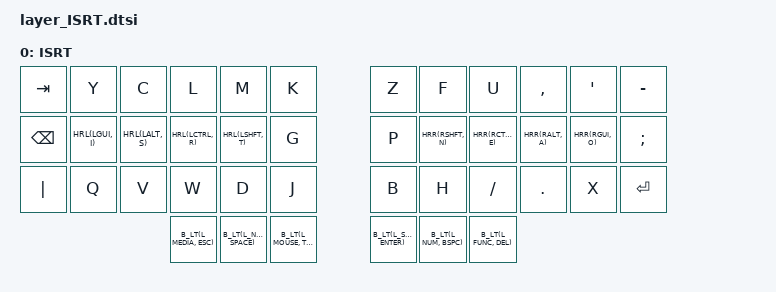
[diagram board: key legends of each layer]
/ {
    keymap {
        compatible = "zmk,keymap";

        isrt {
            // -----------------------------------------------------------------------------------------
            // |  TAB |  Y  |  C  |  L  |  M  |  K  |         |  Z  |  F   |  U  |  ,  |  '  |  -   |
            // | BKSP |  I  |  S  |  R  |  T  |  G  |         |  P  |  N   |  E  |  A  |  O  |  ;   |
            // |   |  |  Q  |  V  |  W  |  D  |  J  |         |  B  |  H   |  /  |  .  |  X  | ENT  |
            //                    | ESC | SPC | TAB |         | ENT | BSPC | DEL |

            display-name = "ISRT";
            bindings = <
&kp TAB   &kp Y        &kp C        &kp L          &kp M          &kp K            &kp Z          &kp F         &kp U         &kp COMMA    &kp SQT      &kp MINUS
&kp BSPC  HRL(LGUI, I)  HRL(LALT, S)  HRL(LCTRL, R)  HRL(LSHFT, T)  &kp G          &kp P          HRR(RSHFT, N)  HRR(RCTRL, E)  HRR(RALT, A)  HRR(RGUI, O)  &kp SEMI
&kp PIPE  &kp Q        &kp V        &kp W          &kp D          &kp J            &kp B          &kp H         &kp SLASH     &kp DOT      &kp X        &kp RET
                       B_LT(L_MEDIA, ESC)  B_LT(L_NAV, SPACE)  B_LT(L_MOUSE, TAB)        B_LT(L_SYM, ENTER)  B_LT(L_NUM, BSPC)   B_LT(L_FUNC, DEL)
            >;
        };
    };
};

/*
ISRT:
TAB   Y C L M K		Z F U , ' -
BSPC  I S R T G		P N E A O ;
|     Q V W D J		B H / . X ENT
   SFT MOD   BSPC SPACE
*/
